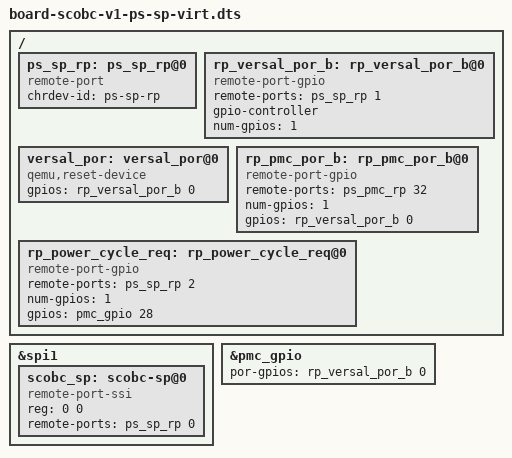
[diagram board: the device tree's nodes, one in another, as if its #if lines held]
/*
 * SC-OBC V1 QEMU hardware description, with the safety processor
 *
 * The MULTI_ARCH build connects SPI1 to the SPI target of the safety
 * processor QEMU (board-scobc-v1-sp-virt.dtb) over remote-port. Both
 * sides use the same adaptor node name, so they meet on the socket
 * qemu-rport-_ps_sp_rp@0 in the common -machine-path. The PMC instance
 * must use board-scobc-v1-pmc-sp-virt.dtb.
 */

#include "board-scobc-v1-ps-virt.dts"

#ifdef MULTI_ARCH
/ {
	ps_sp_rp: ps_sp_rp@0 {
		compatible = "remote-port";
		chrdev-id = "ps-sp-rp";
	};

	/* Versal POR_B, driven by the MPPC of the safety processor */
	rp_versal_por_b: rp_versal_por_b@0 {
		compatible = "remote-port-gpio";
		remote-ports = <&ps_sp_rp 1>;
		gpio-controller;
		#gpio-cells = <1>;
		num-gpios = <1>;
	};

	/*
	 * Versal starts up on the rising edge of POR_B. The reset device
	 * cannot hold the instance in reset, so reset it when POR_B is
	 * released instead of while it is asserted.
	 */
	versal_por: versal_por@0 {
		compatible = "qemu,reset-device";
		gpios = <&rp_versal_por_b 0>;
	};

	/*
	 * POR resets the whole Versal. Forward POR_B to the PMC instance
	 * (board-scobc-v1-pmc-sp-virt.dtb), so the ROM and PLM start over.
	 */
	rp_pmc_por_b: rp_pmc_por_b@0 {
		compatible = "remote-port-gpio";
		remote-ports = <&ps_pmc_rp 32>;
		num-gpios = <1>;
		gpios = <&rp_versal_por_b 0>;
	};

	/* PMC MIO28 to the Power Cycle Request input of the MPPC */
	rp_power_cycle_req: rp_power_cycle_req@0 {
		compatible = "remote-port-gpio";
		remote-ports = <&ps_sp_rp 2>;
		num-gpios = <1>;
		gpios = <&pmc_gpio 28>;
	};
};

&spi1 {
	/* SPI target of the safety processor, on its CS0 */
	scobc_sp: scobc-sp@0 {
		compatible = "remote-port-ssi";
		reg = <0 0>;
		remote-ports = <&ps_sp_rp 0>;
	};
};

&pmc_gpio {
	/*
	 * POR clears the pins, which QEMU otherwise keeps across resets.
	 * Without this, a stale MIO28 raises Power Cycle Request again
	 * once software touches the GPIO after the reset.
	 */
	por-gpios = <&rp_versal_por_b 0>;
};
#endif
